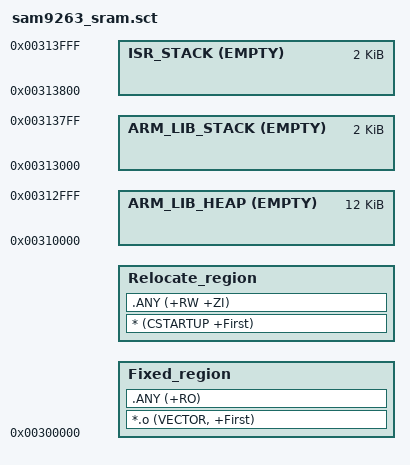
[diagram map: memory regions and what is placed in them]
;*****************************************************************
;* SAM9263 linker scatter file (running code from internal SRAM) *
;*****************************************************************

Load_region 0x300000 0x14000
{    
   Fixed_region 0x300000
   {
      *.o (VECTOR, +First)
      .ANY (+RO)
   }
   
   Relocate_region +0 
   {
      * (CSTARTUP +First)
      .ANY (+RW +ZI)
   }
   
   ScatterAssert((ImageLength(Fixed_region) + ImageLength(Relocate_region)) <  0x10000)
   
   ARM_LIB_HEAP 0x310000 EMPTY 0x3000
   {
   }
   
   ARM_LIB_STACK 0x313800 EMPTY -0x800
   {
   }
   
   ISR_STACK 0x314000 EMPTY -0x800
   {
   }
}
